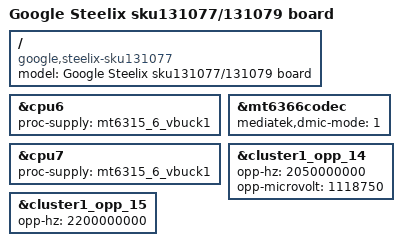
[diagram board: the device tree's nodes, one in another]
// SPDX-License-Identifier: (GPL-2.0 OR MIT)
/*
 * Copyright 2022 Google LLC
 */

/dts-v1/;
#include "mt8186-corsola-steelix.dtsi"
#include "mt6315.dtsi"

/ {
	model = "Google Steelix sku131077/131079 board";
	compatible = "google,steelix-sku131077", "google,steelix-sku131079",
		     "google,steelix", "mediatek,mt8186";
};

&cpu6 {
	proc-supply = <&mt6315_6_vbuck1>;
};

&cpu7 {
	proc-supply = <&mt6315_6_vbuck1>;
};

&mt6366codec {
	mediatek,dmic-mode = <1>; /* one-wire */
};

&cluster1_opp_14 {
	opp-hz = /bits/ 64 <2050000000>;
	opp-microvolt = <1118750>;
};

&cluster1_opp_15 {
	opp-hz = /bits/ 64 <2200000000>;
};
